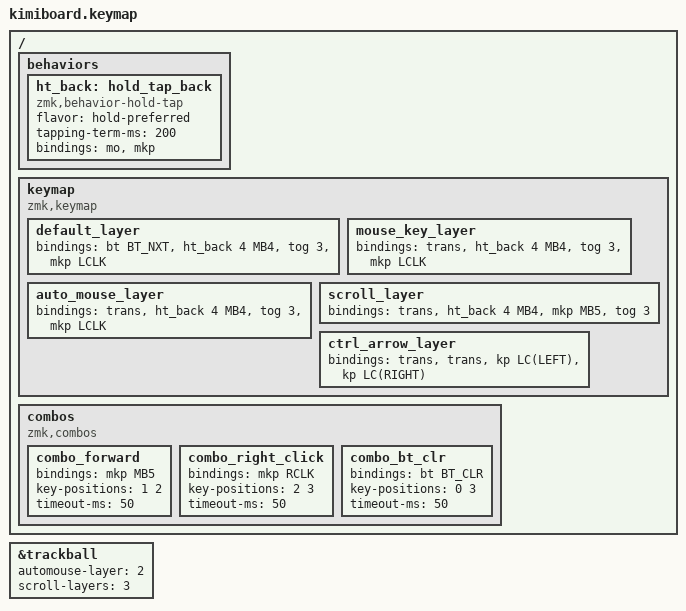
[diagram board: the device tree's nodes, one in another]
#include <behaviors.dtsi>
#include <dt-bindings/zmk/bt.h>
#include <dt-bindings/zmk/keys.h>
#include <dt-bindings/zmk/mouse.h>
#include <dt-bindings/zmk/pointing.h>
#include <behaviors/rgbled_widget.dtsi>

&trackball {
    automouse-layer = <2>;
    scroll-layers = <3>;
};


/ {
    behaviors {
        // 1キー: タップ=戻る(MB4) / ホールド=Ctrl矢印レイヤー(4)
        ht_back: hold_tap_back {
            compatible = "zmk,behavior-hold-tap";
            #binding-cells = <2>;
            flavor = "hold-preferred";
            tapping-term-ms = <200>;
            bindings = <&mo>, <&mkp>;
        };
    };

    keymap {
        compatible = "zmk,keymap";

        default_layer {
            bindings = <
                // pos0(リセット隣)  pos1=戻る(ホールドでCtrl矢印)  pos2=スクロールトグル  pos3=左クリック
                &bt BT_NXT  &ht_back 4 MB4  &tog 3  &mkp LCLK
            >;
	};

    mouse_key_layer {
            bindings = <
                &trans  &ht_back 4 MB4  &tog 3  &mkp LCLK
        >;
    };

    auto_mouse_layer {
            // トラックボール移動中。常に同じ割り当てにする
            bindings = <
                &trans  &ht_back 4 MB4  &tog 3  &mkp LCLK
        >;
    };

    scroll_layer {
            // スクロール中。pos3(key3)でスクロール解除(レイヤー3 OFF)
            bindings = <
                &trans  &ht_back 4 MB4  &mkp MB5  &tog 3
        >;
    };

    ctrl_arrow_layer {
            // 1キーをホールド中。pos2=Ctrl+← / pos3=Ctrl+→
            bindings = <
                &trans  &trans  &kp LC(LEFT)  &kp LC(RIGHT)
        >;
    };



    };

    combos {
        compatible = "zmk,combos";

        // pos1 + pos2 = (□ - ■ ■ □)
            // 進む（同時押し。押しながらはCtrl+←）

        combo_forward {
            bindings = <&mkp MB5>;
            key-positions = <1 2>;
            timeout-ms = <50>;
        };

        // pos2 + pos3 = (□ - □ ■ ■)
            // 右クリック

        combo_right_click {
            bindings = <&mkp RCLK>;
            key-positions = <2 3>;
            timeout-ms = <50>;
        };

        // pos0 + pos3 = (■ - □ □ ■)
            // 現在の接続先のBT接続情報を消去

        combo_bt_clr {
            bindings = <&bt BT_CLR>;
            key-positions = <0 3>;
            timeout-ms = <50>;
        };


    };

};
